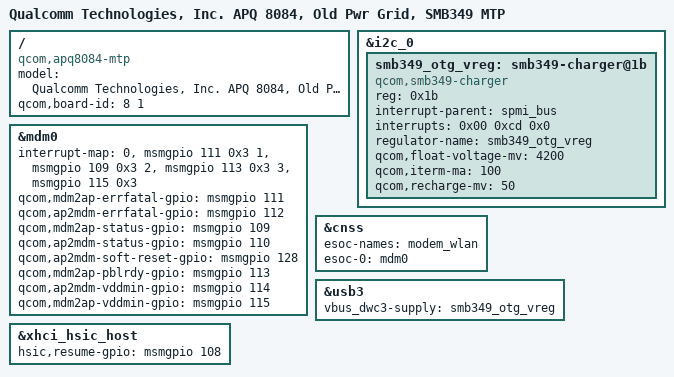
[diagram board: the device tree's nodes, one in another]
/* Copyright (c) 2013-2014, The Linux Foundation. All rights reserved.
 *
 * This program is free software; you can redistribute it and/or modify
 * it under the terms of the GNU General Public License version 2 and
 * only version 2 as published by the Free Software Foundation.
 *
 * This program is distributed in the hope that it will be useful,
 * but WITHOUT ANY WARRANTY; without even the implied warranty of
 * MERCHANTABILITY or FITNESS FOR A PARTICULAR PURPOSE.  See the
 * GNU General Public License for more details.
 */

/dts-v1/;

#include "apq8084.dtsi"
#include "apq8084-old-pwr-grid.dtsi"
#include "apq8084-mtp.dtsi"

/ {
	model = "Qualcomm Technologies, Inc. APQ 8084, Old Pwr Grid, SMB349 MTP";
	compatible = "qcom,apq8084-mtp", "qcom,apq8084", "qcom,mtp";
	qcom,board-id = <8 1>;
};

&i2c_0 {
	smb349_otg_vreg: smb349-charger@1b {
		compatible = "qcom,smb349-charger";
		reg = <0x1b>;
		interrupt-parent = <&spmi_bus>;
		interrupts = <0x00 0xcd 0x0>; /* PMA8084 GPIO 14 */
		regulator-name = "smb349_otg_vreg";
		qcom,float-voltage-mv = <4200>;
		qcom,iterm-ma = <100>;
		qcom,recharge-mv = <50>;
	};
};

&mdm0 {
	interrupt-map = <0 &msmgpio 111 0x3
			1 &msmgpio 109 0x3
			2 &msmgpio 113 0x3
			3 &msmgpio 115 0x3>;
	qcom,mdm2ap-errfatal-gpio = <&msmgpio 111 0x00>;
	qcom,ap2mdm-errfatal-gpio = <&msmgpio 112 0x00>;
	qcom,mdm2ap-status-gpio   = <&msmgpio 109 0x00>;
	qcom,ap2mdm-status-gpio   = <&msmgpio 110 0x00>;
	qcom,ap2mdm-soft-reset-gpio = <&msmgpio 128 0x00>;
	qcom,mdm2ap-pblrdy-gpio = <&msmgpio 113 0x00>;
	qcom,ap2mdm-vddmin-gpio = <&msmgpio 114 0x00>;
	qcom,mdm2ap-vddmin-gpio = <&msmgpio 115 0x00>;
	status = "ok";
};

&cnss {
	esoc-names = "modem_wlan";
	esoc-0 = <&mdm0>;
};

&usb3 {
	vbus_dwc3-supply = <&smb349_otg_vreg>;
};

&xhci_hsic_host {
	hsic,resume-gpio = <&msmgpio 108 0x00>;
};
